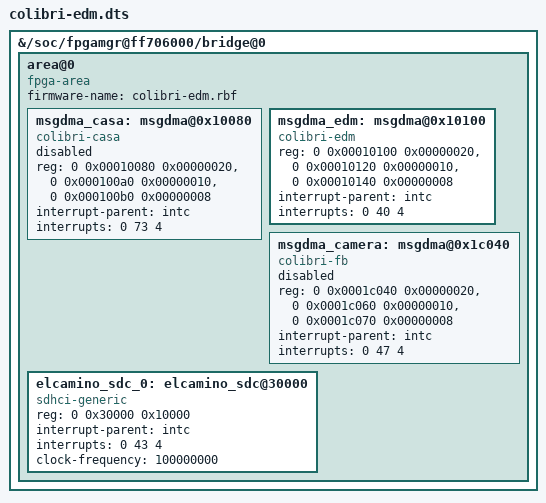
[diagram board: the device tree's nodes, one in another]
/* Device tree overlay example for FPGA configuration and device probing */

/dts-v1/ /plugin/;

/ {
	fragment@0 {
		/* controlling bridge */
		target-path = "/soc/fpgamgr@ff706000/bridge@0";
		__overlay__ {
			#address-cells = <1>;
	                #size-cells = <1>;

			area@0 {
				compatible = "fpga-area";

				#address-cells = <2>;
				#size-cells = <1>;
				/* We use one bridge, so one range */
				ranges = <0 0x00000000 0xff200000 0x00040000>;

				firmware-name = "colibri-edm.rbf";

				msgdma_casa: msgdma@0x10080 {
					/* XXX DS: this one has to be changed either to shared DMA or FIFO */
					status = "disabled";
					compatible = "colibri-casa";
					reg = <0 0x00010080 0x00000020>,
					      <0 0x000100a0 0x00000010>,
					      <0 0x000100b0 0x00000008>;
					reg-names = "CSR", "Descriptor_Slave", "Response_Slave";
					interrupt-parent = <&intc>;
					interrupts = <0 73 4>;
				}; //end msgdma@0xff210080 (msgdma_casa)

				msgdma_edm: msgdma@0x10100 {
					/* status = "disabled"; */
					compatible = "colibri-edm";
					reg = <0 0x00010100 0x00000020>,
					      <0 0x00010120 0x00000010>,
					      <0 0x00010140 0x00000008>;
					reg-names = "CSR", "Descriptor_Slave", "Response_Slave";
					interrupt-parent = <&intc>;
					interrupts = <0 40 4>;
				}; //end unknown@0xff2110100 (msgdma_edm)

				msgdma_camera: msgdma@0x1c040 {
					status = "disabled";
					compatible = "colibri-fb";
					reg = <0 0x0001c040 0x00000020>,
					      <0 0x0001c060 0x00000010>,
					      <0 0x0001c070 0x00000008>;
					reg-names = "csr", "descriptor_slave", "response";
					interrupt-parent = <&intc>;
					interrupts = <0 47 4>;
				}; //end msgdma@0xff21c040 (msgdma_camera)

				elcamino_sdc_0: elcamino_sdc@30000 {
					/*status = "disabled";*/
					compatible = "sdhci-generic", "generic-sdhci";
					reg = <0 0x30000 0x10000>;
					interrupt-parent = <&intc>;
					interrupts = <0 43 4>;
					clock-frequency = <100000000>;
				};

			};
		};
	};
};
